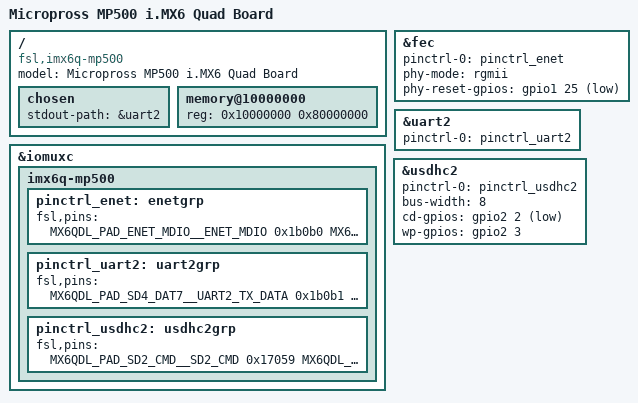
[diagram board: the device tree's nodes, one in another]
// SPDX-License-Identifier: GPL-2.0+

/dts-v1/;

#include "imx6q.dtsi"

#include <dt-bindings/clock/imx6qdl-clock.h>
#include <dt-bindings/gpio/gpio.h>
#include <dt-bindings/input/input.h>

/ {
	model = "Micropross MP500 i.MX6 Quad Board";
	compatible = "fsl,imx6q-mp500", "fsl,imx6q";

	chosen {
		stdout-path = &uart2;
	};

	memory@10000000 {
		device_type = "memory";
		reg = <0x10000000 0x80000000>;
	};

};

&fec {
	pinctrl-names = "default";
	pinctrl-0 = <&pinctrl_enet>;
	phy-mode = "rgmii";
	phy-reset-gpios = <&gpio1 25 GPIO_ACTIVE_LOW>;
	status = "okay";
};

&iomuxc {
	pinctrl-names = "default";

	imx6q-mp500 {

		pinctrl_enet: enetgrp {
			fsl,pins = <
				MX6QDL_PAD_ENET_MDIO__ENET_MDIO		0x1b0b0
				MX6QDL_PAD_ENET_MDC__ENET_MDC		0x1b0b0
				MX6QDL_PAD_RGMII_TXC__RGMII_TXC		0x1b030
				MX6QDL_PAD_RGMII_TD0__RGMII_TD0		0x1b030
				MX6QDL_PAD_RGMII_TD1__RGMII_TD1		0x1b030
				MX6QDL_PAD_RGMII_TD2__RGMII_TD2		0x1b030
				MX6QDL_PAD_RGMII_TD3__RGMII_TD3		0x1b030
				MX6QDL_PAD_RGMII_TX_CTL__RGMII_TX_CTL	0x1b030
				MX6QDL_PAD_ENET_REF_CLK__ENET_TX_CLK	0x1b0b0
				MX6QDL_PAD_RGMII_RXC__RGMII_RXC		0x1b030
				MX6QDL_PAD_RGMII_RD0__RGMII_RD0		0x1b030
				MX6QDL_PAD_RGMII_RD1__RGMII_RD1		0x1b030
				MX6QDL_PAD_RGMII_RD2__RGMII_RD2		0x1b030
				MX6QDL_PAD_RGMII_RD3__RGMII_RD3		0x1b030
				MX6QDL_PAD_RGMII_RX_CTL__RGMII_RX_CTL	0x1b030
				MX6QDL_PAD_GPIO_16__ENET_REF_CLK	0x4001b0a8
			>;
		};

		pinctrl_uart2: uart2grp {
			fsl,pins = <
				MX6QDL_PAD_SD4_DAT7__UART2_TX_DATA	0x1b0b1
				MX6QDL_PAD_SD4_DAT4__UART2_RX_DATA	0x1b0b1
			>;
		};
		pinctrl_usdhc2: usdhc2grp {
			fsl,pins = <
				MX6QDL_PAD_SD2_CMD__SD2_CMD		0x17059
				MX6QDL_PAD_SD2_CLK__SD2_CLK		0x10059
				MX6QDL_PAD_SD2_DAT0__SD2_DATA0		0x17059
				MX6QDL_PAD_SD2_DAT1__SD2_DATA1		0x17059
				MX6QDL_PAD_SD2_DAT2__SD2_DATA2		0x17059
				MX6QDL_PAD_SD2_DAT3__SD2_DATA3		0x17059
				MX6QDL_PAD_NANDF_D4__SD2_DATA4		0x17059
				MX6QDL_PAD_NANDF_D5__SD2_DATA5		0x17059
				MX6QDL_PAD_NANDF_D6__SD2_DATA6		0x17059
				MX6QDL_PAD_NANDF_D7__SD2_DATA7		0x17059
			>;
		};

	};

};

&uart2 {
	pinctrl-names = "default";
	pinctrl-0 = <&pinctrl_uart2>;
	status = "okay";
};

&usdhc2 {
	pinctrl-names = "default";
	pinctrl-0 = <&pinctrl_usdhc2>;
	bus-width = <8>;
	cd-gpios = <&gpio2 2 GPIO_ACTIVE_LOW>;
	wp-gpios = <&gpio2 3 GPIO_ACTIVE_HIGH>;
	status = "okay";
};

